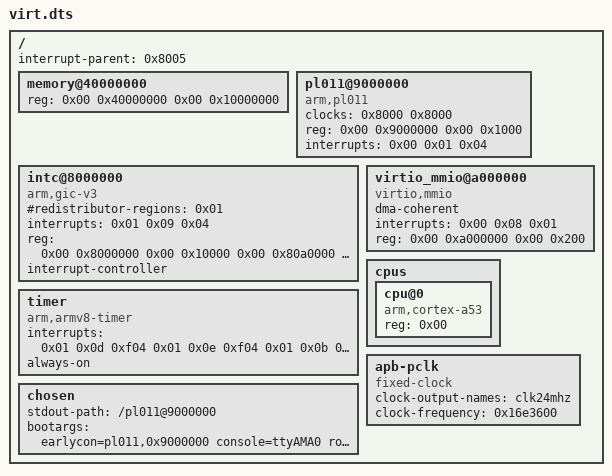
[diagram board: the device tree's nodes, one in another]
/dts-v1/;

/ {
	#size-cells = <0x02>;
	#address-cells = <0x02>;
	interrupt-parent = <0x8005>;

	memory@40000000 {
		reg = <0x00 0x40000000 0x00 0x10000000>;
		device_type = "memory";
	};

	pl011@9000000 {
		clock-names = "uartclk\0apb_pclk";
		clocks = <0x8000 0x8000>;
		reg = <0x00 0x9000000 0x00 0x1000>;
		interrupts = <0x00 0x01 0x04>;
		compatible = "arm,pl011\0arm,primecell";
	};

	intc@8000000 {
		#interrupt-cells = <0x03>;
		#redistributor-regions = <0x01>;
		phandle = <0x8005>;
		interrupts = <0x01 0x09 0x04>;
		reg = <0x00 0x8000000 0x00 0x10000 0x00 0x80a0000 0x00 0x20000>;
		compatible = "arm,gic-v3";
		interrupt-controller;
	};

	virtio_mmio@a000000 {
		dma-coherent;
		interrupts = <0x00 0x08 0x01>;
		reg = <0x00 0xa000000 0x00 0x200>;
		compatible = "virtio,mmio";
	};

	timer {
		interrupts = <0x01 0x0d 0xf04 0x01 0x0e 0xf04 0x01 0x0b 0xf04 0x01 0x0a 0xf04>;
		always-on;
		compatible = "arm,armv8-timer\0arm,armv7-timer";
	};

	cpus {
		#size-cells = <0x00>;
		#address-cells = <0x01>;
		cpu@0 {
			phandle = <0x8004>;
			reg = <0x00>;
			compatible = "arm,cortex-a53";
			device_type = "cpu";
		};
	};

	apb-pclk {
		phandle = <0x8000>;
		clock-output-names = "clk24mhz";
		clock-frequency = <0x16e3600>;
		#clock-cells = <0x00>;
		compatible = "fixed-clock";
	};

	chosen {
		stdout-path = "/pl011@9000000";
		bootargs = "earlycon=pl011,0x9000000 console=ttyAMA0 root=/dev/vda";
	};
};

